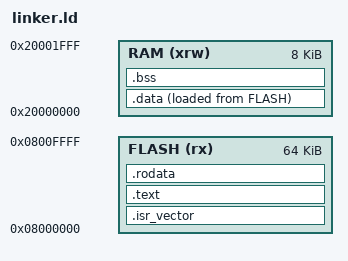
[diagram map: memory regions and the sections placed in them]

ENTRY(Reset_Handler)

MEMORY {
    FLASH (rx) : ORIGIN = 0x08000000, LENGTH = 64K
    RAM (xrw)  : ORIGIN = 0x20000000, LENGTH =  8K
}

_estack = ORIGIN(RAM) + LENGTH(RAM);

SECTIONS {
    .isr_vector : {
        . = ALIGN(4);
        KEEP(*(.isr_vector))
        . = ALIGN(4);
    } >FLASH

    .text : {
        . = ALIGN(4);
        *(.text)
        *(.text*)
        *(.glue_7)      /* glue arm to thumb code */
        *(.glue_7t)     /* glue thumb to arm code */
        *(.eh_frame)

        . = ALIGN(4);
        _etext = .;     /* define a global symbols at end of code */
    } >FLASH

    .rodata : {
        . = ALIGN(4);
        *(.rodata)
        *(.rodata*)
        . = ALIGN(4);
    } >FLASH

    _sidata = LOADADDR(.data);

    .data : {
        . = ALIGN(4);
        _sdata = .;
        *(.data)
        *(.data*)
        . = ALIGN(4);
        _edata = .;
    } >RAM AT>FLASH

    . = ALIGN(4);
    .bss : {
        _sbss = .;
        *(.bss)
        *(.bss*)
        . = ALIGN(4);
        _ebss = .;
    } >RAM
}
